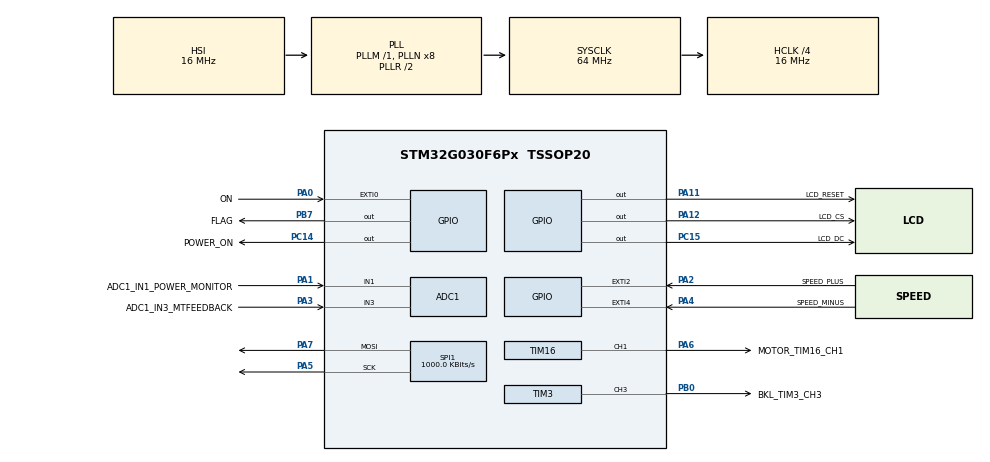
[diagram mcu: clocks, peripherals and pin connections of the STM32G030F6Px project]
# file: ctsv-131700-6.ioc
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ADC1.Channel-0\#ChannelRegularConversion=ADC_CHANNEL_1
ADC1.Channel-1\#ChannelRegularConversion=ADC_CHANNEL_3
ADC1.ContinuousConvMode=ENABLE
ADC1.DMAContinuousRequests=ENABLE
ADC1.EOCSelection=ADC_EOC_SEQ_CONV
ADC1.ExternalTrigConv=ADC_EXTERNALTRIG_T1_TRGO2
ADC1.NbrOfConversion=2
ADC1.NbrOfConversionFlag=1
ADC1.Rank-0\#ChannelRegularConversion=1
ADC1.Rank-1\#ChannelRegularConversion=2
ADC1.SamplingTime-0\#ChannelRegularConversion=ADC_SAMPLINGTIME_COMMON_1
ADC1.SamplingTime-1\#ChannelRegularConversion=ADC_SAMPLINGTIME_COMMON_1
ADC1.SamplingTimeCommon1=ADC_SAMPLETIME_39CYCLES_5
ADC1.SamplingTimeCommon2=ADC_SAMPLETIME_7CYCLES_5
ADC1.SelectedChannel=ADC_CHANNEL_1|ADC_CHANNEL_3
ADC1.TriggerFrequencyMode=ADC_TRIGGER_FREQ_LOW
ADC1.master=1
Dma.ADC1.0.Direction=DMA_PERIPH_TO_MEMORY
Dma.ADC1.0.EventEnable=DISABLE
Dma.ADC1.0.Instance=DMA1_Channel1
Dma.ADC1.0.MemDataAlignment=DMA_MDATAALIGN_HALFWORD
Dma.ADC1.0.MemInc=DMA_MINC_ENABLE
Dma.ADC1.0.Mode=DMA_CIRCULAR
Dma.ADC1.0.PeriphDataAlignment=DMA_PDATAALIGN_HALFWORD
Dma.ADC1.0.PeriphInc=DMA_PINC_DISABLE
Dma.ADC1.0.Polarity=HAL_DMAMUX_REQ_GEN_RISING
Dma.ADC1.0.Priority=DMA_PRIORITY_LOW
Dma.ADC1.0.RequestNumber=1
Dma.ADC1.0.SignalID=NONE
Dma.ADC1.0.SyncEnable=DISABLE
Dma.ADC1.0.SyncPolarity=HAL_DMAMUX_SYNC_NO_EVENT
Dma.ADC1.0.SyncRequestNumber=1
Dma.ADC1.0.SyncSignalID=NONE
Dma.Request0=ADC1
Mcu.Family=STM32G0
Mcu.Name=STM32G030F6Px
Mcu.Package=TSSOP20
NVIC.DMA1_Channel1_IRQn=true\:0\:0\:false\:false\:true\:false\:true
NVIC.EXTI0_1_IRQn=true\:0\:0\:false\:false\:true\:true\:true
NVIC.EXTI2_3_IRQn=true\:0\:0\:false\:false\:true\:true\:true
NVIC.EXTI4_15_IRQn=true\:0\:0\:false\:false\:true\:true\:true
NVIC.TIM16_IRQn=true\:0\:0\:false\:false\:true\:true\:true
NVIC.TIM17_IRQn=true\:0\:0\:false\:false\:true\:true\:true
PA0.GPIO_Label=ON
PA0.GPIO_ModeDefaultEXTI=GPIO_MODE_IT_FALLING
PA0.GPIO_PuPd=GPIO_PULLUP
PA0.Signal=GPXTI0
PA1.GPIO_Label=ADC1_IN1_POWER_MONITOR
PA1.Mode=IN1
PA1.Signal=ADC1_IN1
PA11\ [PA9].GPIO_Label=LCD_RESET
PA11\ [PA9].Signal=GPIO_Output
PA12\ [PA10].GPIO_Label=LCD_CS
PA12\ [PA10].Signal=GPIO_Output
PA13.Mode=Serial_Wire
PA13.Signal=SYS_SWDIO
PA14-BOOT0.Mode=Serial_Wire
PA14-BOOT0.Signal=SYS_SWCLK
PA2.GPIO_Label=SPEED_PLUS
PA2.GPIO_ModeDefaultEXTI=GPIO_MODE_IT_FALLING
PA2.GPIO_PuPd=GPIO_PULLUP
PA2.Signal=GPXTI2
PA3.GPIO_Label=ADC1_IN3_MTFEEDBACK
PA3.Mode=IN3
PA3.Signal=ADC1_IN3
PA4.GPIO_Label=SPEED_MINUS
PA4.GPIO_ModeDefaultEXTI=GPIO_MODE_IT_FALLING
PA4.GPIO_PuPd=GPIO_PULLUP
PA4.Signal=GPXTI4
PA5.Mode=TX_Only_Simplex_Unidirect_Master
PA5.Signal=SPI1_SCK
PA6.GPIO_Label=MOTOR_TIM16_CH1
PA6.Signal=S_TIM16_CH1
PA7.Mode=TX_Only_Simplex_Unidirect_Master
PA7.Signal=SPI1_MOSI
PB0.GPIO_Label=BKL_TIM3_CH3
PB0.Signal=S_TIM3_CH3
PB7.GPIO_Label=FLAG
PB7.Signal=GPIO_Output
PC14-OSC32_IN\ (PC14).GPIO_Label=POWER_ON
PC14-OSC32_IN\ (PC14).PinState=GPIO_PIN_SET
PC14-OSC32_IN\ (PC14).Signal=GPIO_Output
PC15-OSC32_OUT\ (PC15).GPIO_Label=LCD_DC
PC15-OSC32_OUT\ (PC15).Signal=GPIO_Output
ProjectManager.HeapSize=0x200
ProjectManager.StackSize=0x400
ProjectManager.TargetToolchain=STM32CubeIDE
RCC.ADCCLockSelection=RCC_ADCCLKSOURCE_PLLADC
RCC.ADCFreq_Value=4000000
RCC.AHBCLKDivider=RCC_SYSCLK_DIV4
RCC.AHBFreq_Value=16000000
RCC.APB1CLKDivider=RCC_HCLK_DIV8
RCC.CortexFreq_Value=16000000
RCC.DATA_CACHE_ENABLE=0
RCC.EXTERNAL_CLOCK_VALUE=12288000
RCC.HCLKFreq_Value=16000000
RCC.HSE_VALUE=8000000
RCC.HSI_VALUE=16000000
RCC.INSTRUCTION_CACHE_ENABLE=1
RCC.LSE_VALUE=32768
RCC.PLLP=RCC_PLLP_DIV32
RCC.SYSCLKFreq_VALUE=64000000
RCC.SYSCLKSource=RCC_SYSCLKSOURCE_PLLCLK
RCC.USART1CLockSelection=RCC_USART1CLKSOURCE_HSI
RCC.VCOOutputFreq_Value=128000000
RCC.VDD_VALUE=2
SH.S_TIM16_CH1.0=TIM16_CH1,PWM Generation1 CH1
SH.S_TIM3_CH3.0=TIM3_CH3,PWM Generation3 CH3
SPI1.BaudRatePrescaler=SPI_BAUDRATEPRESCALER_2
SPI1.CalculateBaudRate=1000.0 KBits/s
SPI1.Direction=SPI_DIRECTION_2LINES
SPI1.Mode=SPI_MODE_MASTER
SPI1.VirtualType=VM_MASTER
TIM1.Period=20000
TIM1.Prescaler=4
TIM1.TIM_MasterOutputTrigger=TIM_TRGO_UPDATE
TIM1.TIM_MasterOutputTrigger2=TIM_TRGO2_UPDATE
TIM16.Channel=TIM_CHANNEL_1
TIM16.Period=10000
TIM16.Prescaler=32
TIM16.Pulse=500
TIM17.Period=10000
TIM17.Prescaler=640
TIM3.Channel-PWM\ Generation3\ CH3=TIM_CHANNEL_3
TIM3.Period=10000
TIM3.Prescaler=4
TIM3.Pulse-PWM\ Generation3\ CH3=5000
VP_TIM16_VS_ClockSourceINT.Mode=Enable_Timer
VP_TIM17_VS_ClockSourceINT.Mode=Enable_Timer
VP_TIM1_VS_ClockSourceINT.Mode=Internal
board=custom

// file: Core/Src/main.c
/* USER CODE BEGIN Header */
/**
  ******************************************************************************
  * @file           : main.c
  * @brief          : Main program body
  ******************************************************************************
  * @attention
  *
  * <h2><center>&copy; Copyright (c) 2021 STMicroelectronics.
  * All rights reserved.</center></h2>
  *
  * This software component is licensed by ST under BSD 3-Clause license,
  * the "License"; You may not use this file except in compliance with the
  * License. You may obtain a copy of the License at:
  *                        opensource.org/licenses/BSD-3-Clause
  *
  ******************************************************************************
  */
/* USER CODE END Header */
#include "main.h"

ADC_HandleTypeDef hadc1;
DMA_HandleTypeDef hdma_adc1;

SPI_HandleTypeDef hspi1;

TIM_HandleTypeDef htim1;
TIM_HandleTypeDef htim3;
TIM_HandleTypeDef htim16;
TIM_HandleTypeDef htim17;

void SystemClock_Config(void);
static void MX_GPIO_Init(void);
static void MX_DMA_Init(void);
static void MX_ADC1_Init(void);
static void MX_SPI1_Init(void);
static void MX_TIM3_Init(void);
static void MX_TIM16_Init(void);
static void MX_TIM17_Init(void);
static void MX_TIM1_Init(void);

int main(void)
{

  /* MCU Configuration--------------------------------------------------------*/

  /* Reset of all peripherals, Initializes the Flash interface and the Systick. */
  HAL_Init();

  /* Configure the system clock */
  SystemClock_Config();

  /* Initialize all configured peripherals */
  MX_GPIO_Init();
  MX_DMA_Init();
  MX_ADC1_Init();
  MX_SPI1_Init();
  MX_TIM3_Init();
  MX_TIM16_Init();
  MX_TIM17_Init();
  MX_TIM1_Init();
  /* USER CODE BEGIN 2 */
  SurgyInit();
  /* USER CODE END 2 */

  /* Infinite loop */
  /* USER CODE BEGIN WHILE */
  while (1)
  {
	  SurgyMainLoop();
    /* USER CODE END WHILE */

  }
}

void SystemClock_Config(void)
{
  RCC_OscInitTypeDef RCC_OscInitStruct = {0};
  RCC_ClkInitTypeDef RCC_ClkInitStruct = {0};
  RCC_PeriphCLKInitTypeDef PeriphClkInit = {0};

  /** Configure the main internal regulator output voltage
  */
  HAL_PWREx_ControlVoltageScaling(PWR_REGULATOR_VOLTAGE_SCALE1);
  /** Initializes the RCC Oscillators according to the specified parameters
  * in the RCC_OscInitTypeDef structure.
  */
  RCC_OscInitStruct.OscillatorType = RCC_OSCILLATORTYPE_HSI;
  RCC_OscInitStruct.HSIState = RCC_HSI_ON;
  RCC_OscInitStruct.HSIDiv = RCC_HSI_DIV1;
  RCC_OscInitStruct.HSICalibrationValue = RCC_HSICALIBRATION_DEFAULT;
  RCC_OscInitStruct.PLL.PLLState = RCC_PLL_ON;
  RCC_OscInitStruct.PLL.PLLSource = RCC_PLLSOURCE_HSI;
  RCC_OscInitStruct.PLL.PLLM = RCC_PLLM_DIV1;
  RCC_OscInitStruct.PLL.PLLN = 8;
  RCC_OscInitStruct.PLL.PLLP = RCC_PLLP_DIV32;
  RCC_OscInitStruct.PLL.PLLR = RCC_PLLR_DIV2;
  if (HAL_RCC_OscConfig(&RCC_OscInitStruct) != HAL_OK)
  {
    Error_Handler();
  }
  /** Initializes the CPU, AHB and APB buses clocks
  */
  RCC_ClkInitStruct.ClockType = RCC_CLOCKTYPE_HCLK|RCC_CLOCKTYPE_SYSCLK
                              |RCC_CLOCKTYPE_PCLK1;
  RCC_ClkInitStruct.SYSCLKSource = RCC_SYSCLKSOURCE_PLLCLK;
  RCC_ClkInitStruct.AHBCLKDivider = RCC_SYSCLK_DIV4;
  RCC_ClkInitStruct.APB1CLKDivider = RCC_HCLK_DIV8;

  if (HAL_RCC_ClockConfig(&RCC_ClkInitStruct, FLASH_LATENCY_0) != HAL_OK)
  {
    Error_Handler();
  }
  /** Initializes the peripherals clocks
  */
  PeriphClkInit.PeriphClockSelection = RCC_PERIPHCLK_ADC;
  PeriphClkInit.AdcClockSelection = RCC_ADCCLKSOURCE_PLLADC;
  if (HAL_RCCEx_PeriphCLKConfig(&PeriphClkInit) != HAL_OK)
  {
    Error_Handler();
  }
}

static void MX_ADC1_Init(void)
{

  ADC_ChannelConfTypeDef sConfig = {0};

  /** Configure the global features of the ADC (Clock, Resolution, Data Alignment and number of conversion)
  */
  hadc1.Instance = ADC1;
  hadc1.Init.ClockPrescaler = ADC_CLOCK_SYNC_PCLK_DIV2;
  hadc1.Init.Resolution = ADC_RESOLUTION_12B;
  hadc1.Init.DataAlign = ADC_DATAALIGN_RIGHT;
  hadc1.Init.ScanConvMode = ADC_SCAN_ENABLE;
  hadc1.Init.EOCSelection = ADC_EOC_SEQ_CONV;
  hadc1.Init.LowPowerAutoWait = DISABLE;
  hadc1.Init.LowPowerAutoPowerOff = DISABLE;
  hadc1.Init.ContinuousConvMode = ENABLE;
  hadc1.Init.NbrOfConversion = 2;
  hadc1.Init.DiscontinuousConvMode = DISABLE;
  hadc1.Init.ExternalTrigConv = ADC_EXTERNALTRIG_T1_TRGO2;
  hadc1.Init.ExternalTrigConvEdge = ADC_EXTERNALTRIGCONVEDGE_RISING;
  hadc1.Init.DMAContinuousRequests = ENABLE;
  hadc1.Init.Overrun = ADC_OVR_DATA_PRESERVED;
  hadc1.Init.SamplingTimeCommon1 = ADC_SAMPLETIME_39CYCLES_5;
  hadc1.Init.SamplingTimeCommon2 = ADC_SAMPLETIME_7CYCLES_5;
  hadc1.Init.OversamplingMode = DISABLE;
  hadc1.Init.TriggerFrequencyMode = ADC_TRIGGER_FREQ_LOW;
  if (HAL_ADC_Init(&hadc1) != HAL_OK)
  {
    Error_Handler();
  }
  /** Configure Regular Channel
  */
  sConfig.Channel = ADC_CHANNEL_1;
  sConfig.Rank = ADC_REGULAR_RANK_1;
  sConfig.SamplingTime = ADC_SAMPLINGTIME_COMMON_1;
  if (HAL_ADC_ConfigChannel(&hadc1, &sConfig) != HAL_OK)
  {
    Error_Handler();
  }
  /** Configure Regular Channel
  */
  sConfig.Channel = ADC_CHANNEL_3;
  sConfig.Rank = ADC_REGULAR_RANK_2;
  if (HAL_ADC_ConfigChannel(&hadc1, &sConfig) != HAL_OK)
  {
    Error_Handler();
  }

}

static void MX_SPI1_Init(void)
{

  /* SPI1 parameter configuration*/
  hspi1.Instance = SPI1;
  hspi1.Init.Mode = SPI_MODE_MASTER;
  hspi1.Init.Direction = SPI_DIRECTION_2LINES;
  hspi1.Init.DataSize = SPI_DATASIZE_8BIT;
  hspi1.Init.CLKPolarity = SPI_POLARITY_LOW;
  hspi1.Init.CLKPhase = SPI_PHASE_1EDGE;
  hspi1.Init.NSS = SPI_NSS_SOFT;
  hspi1.Init.BaudRatePrescaler = SPI_BAUDRATEPRESCALER_2;
  hspi1.Init.FirstBit = SPI_FIRSTBIT_MSB;
  hspi1.Init.TIMode = SPI_TIMODE_DISABLE;
  hspi1.Init.CRCCalculation = SPI_CRCCALCULATION_DISABLE;
  hspi1.Init.CRCPolynomial = 7;
  hspi1.Init.CRCLength = SPI_CRC_LENGTH_DATASIZE;
  hspi1.Init.NSSPMode = SPI_NSS_PULSE_ENABLE;
  if (HAL_SPI_Init(&hspi1) != HAL_OK)
  {
    Error_Handler();
  }

}

static void MX_TIM1_Init(void)
{

  TIM_ClockConfigTypeDef sClockSourceConfig = {0};
  TIM_MasterConfigTypeDef sMasterConfig = {0};
  TIM_BreakDeadTimeConfigTypeDef sBreakDeadTimeConfig = {0};

  htim1.Instance = TIM1;
  htim1.Init.Prescaler = 4;
  htim1.Init.CounterMode = TIM_COUNTERMODE_UP;
  htim1.Init.Period = 20000;
  htim1.Init.ClockDivision = TIM_CLOCKDIVISION_DIV1;
  htim1.Init.RepetitionCounter = 0;
  htim1.Init.AutoReloadPreload = TIM_AUTORELOAD_PRELOAD_DISABLE;
  if (HAL_TIM_Base_Init(&htim1) != HAL_OK)
  {
    Error_Handler();
  }
  sClockSourceConfig.ClockSource = TIM_CLOCKSOURCE_INTERNAL;
  if (HAL_TIM_ConfigClockSource(&htim1, &sClockSourceConfig) != HAL_OK)
  {
    Error_Handler();
  }
  sMasterConfig.MasterOutputTrigger = TIM_TRGO_UPDATE;
  sMasterConfig.MasterOutputTrigger2 = TIM_TRGO2_UPDATE;
  sMasterConfig.MasterSlaveMode = TIM_MASTERSLAVEMODE_DISABLE;
  if (HAL_TIMEx_MasterConfigSynchronization(&htim1, &sMasterConfig) != HAL_OK)
  {
    Error_Handler();
  }
  sBreakDeadTimeConfig.BreakAFMode = TIM_BREAK_AFMODE_INPUT;
  sBreakDeadTimeConfig.Break2AFMode = TIM_BREAK_AFMODE_INPUT;
  if (HAL_TIMEx_ConfigBreakDeadTime(&htim1, &sBreakDeadTimeConfig) != HAL_OK)
  {
    Error_Handler();
  }

}

static void MX_TIM3_Init(void)
{

  TIM_MasterConfigTypeDef sMasterConfig = {0};
  TIM_OC_InitTypeDef sConfigOC = {0};

  htim3.Instance = TIM3;
  htim3.Init.Prescaler = 4;
  htim3.Init.CounterMode = TIM_COUNTERMODE_UP;
  htim3.Init.Period = 10000;
  htim3.Init.ClockDivision = TIM_CLOCKDIVISION_DIV1;
  htim3.Init.AutoReloadPreload = TIM_AUTORELOAD_PRELOAD_DISABLE;
  if (HAL_TIM_PWM_Init(&htim3) != HAL_OK)
  {
    Error_Handler();
  }
  sMasterConfig.MasterOutputTrigger = TIM_TRGO_RESET;
  sMasterConfig.MasterSlaveMode = TIM_MASTERSLAVEMODE_DISABLE;
  if (HAL_TIMEx_MasterConfigSynchronization(&htim3, &sMasterConfig) != HAL_OK)
  {
    Error_Handler();
  }
  sConfigOC.OCMode = TIM_OCMODE_PWM1;
  sConfigOC.Pulse = 5000;
  sConfigOC.OCPolarity = TIM_OCPOLARITY_HIGH;
  sConfigOC.OCFastMode = TIM_OCFAST_DISABLE;
  if (HAL_TIM_PWM_ConfigChannel(&htim3, &sConfigOC, TIM_CHANNEL_3) != HAL_OK)
  {
    Error_Handler();
  }
  HAL_TIM_MspPostInit(&htim3);

}

static void MX_TIM16_Init(void)
{

  TIM_OC_InitTypeDef sConfigOC = {0};
  TIM_BreakDeadTimeConfigTypeDef sBreakDeadTimeConfig = {0};

  htim16.Instance = TIM16;
  htim16.Init.Prescaler = 32;
  htim16.Init.CounterMode = TIM_COUNTERMODE_UP;
  htim16.Init.Period = 10000;
  htim16.Init.ClockDivision = TIM_CLOCKDIVISION_DIV1;
  htim16.Init.RepetitionCounter = 0;
  htim16.Init.AutoReloadPreload = TIM_AUTORELOAD_PRELOAD_DISABLE;
  if (HAL_TIM_Base_Init(&htim16) != HAL_OK)
  {
    Error_Handler();
  }
  if (HAL_TIM_PWM_Init(&htim16) != HAL_OK)
  {
    Error_Handler();
  }
  sConfigOC.OCMode = TIM_OCMODE_PWM1;
  sConfigOC.Pulse = 500;
  sConfigOC.OCPolarity = TIM_OCPOLARITY_HIGH;
  sConfigOC.OCNPolarity = TIM_OCNPOLARITY_HIGH;
  sConfigOC.OCFastMode = TIM_OCFAST_DISABLE;
  sConfigOC.OCIdleState = TIM_OCIDLESTATE_RESET;
  sConfigOC.OCNIdleState = TIM_OCNIDLESTATE_RESET;
  if (HAL_TIM_PWM_ConfigChannel(&htim16, &sConfigOC, TIM_CHANNEL_1) != HAL_OK)
  {
    Error_Handler();
  }
  sBreakDeadTimeConfig.OffStateRunMode = TIM_OSSR_DISABLE;
  sBreakDeadTimeConfig.OffStateIDLEMode = TIM_OSSI_DISABLE;
  sBreakDeadTimeConfig.LockLevel = TIM_LOCKLEVEL_OFF;
  sBreakDeadTimeConfig.DeadTime = 0;
  sBreakDeadTimeConfig.BreakState = TIM_BREAK_DISABLE;
  sBreakDeadTimeConfig.BreakPolarity = TIM_BREAKPOLARITY_HIGH;
  sBreakDeadTimeConfig.BreakFilter = 0;
  sBreakDeadTimeConfig.AutomaticOutput = TIM_AUTOMATICOUTPUT_DISABLE;
  if (HAL_TIMEx_ConfigBreakDeadTime(&htim16, &sBreakDeadTimeConfig) != HAL_OK)
  {
    Error_Handler();
  }
  HAL_TIM_MspPostInit(&htim16);

}

static void MX_TIM17_Init(void)
{

  htim17.Instance = TIM17;
  htim17.Init.Prescaler = 640;
  htim17.Init.CounterMode = TIM_COUNTERMODE_UP;
  htim17.Init.Period = 10000;
  htim17.Init.ClockDivision = TIM_CLOCKDIVISION_DIV1;
  htim17.Init.RepetitionCounter = 0;
  htim17.Init.AutoReloadPreload = TIM_AUTORELOAD_PRELOAD_DISABLE;
  if (HAL_TIM_Base_Init(&htim17) != HAL_OK)
  {
    Error_Handler();
  }

}

static void MX_DMA_Init(void)
{

  /* DMA controller clock enable */
  __HAL_RCC_DMA1_CLK_ENABLE();

  /* DMA interrupt init */
  /* DMA1_Channel1_IRQn interrupt configuration */
  HAL_NVIC_SetPriority(DMA1_Channel1_IRQn, 0, 0);
  HAL_NVIC_EnableIRQ(DMA1_Channel1_IRQn);

}

static void MX_GPIO_Init(void)
{
  GPIO_InitTypeDef GPIO_InitStruct = {0};

  /* GPIO Ports Clock Enable */
  __HAL_RCC_GPIOB_CLK_ENABLE();
  __HAL_RCC_GPIOC_CLK_ENABLE();
  __HAL_RCC_GPIOA_CLK_ENABLE();

  /*Configure GPIO pin Output Level */
  HAL_GPIO_WritePin(FLAG_GPIO_Port, FLAG_Pin, GPIO_PIN_RESET);

  /*Configure GPIO pin Output Level */
  HAL_GPIO_WritePin(POWER_ON_GPIO_Port, POWER_ON_Pin, GPIO_PIN_SET);

  /*Configure GPIO pin Output Level */
  HAL_GPIO_WritePin(LCD_DC_GPIO_Port, LCD_DC_Pin, GPIO_PIN_RESET);

  /*Configure GPIO pin Output Level */
  HAL_GPIO_WritePin(GPIOA, LCD_RESET_Pin|LCD_CS_Pin, GPIO_PIN_RESET);

  /*Configure GPIO pin : FLAG_Pin */
  GPIO_InitStruct.Pin = FLAG_Pin;
  GPIO_InitStruct.Mode = GPIO_MODE_OUTPUT_PP;
  GPIO_InitStruct.Pull = GPIO_NOPULL;
  GPIO_InitStruct.Speed = GPIO_SPEED_FREQ_LOW;
  HAL_GPIO_Init(FLAG_GPIO_Port, &GPIO_InitStruct);

  /*Configure GPIO pins : POWER_ON_Pin LCD_DC_Pin */
  GPIO_InitStruct.Pin = POWER_ON_Pin|LCD_DC_Pin;
  GPIO_InitStruct.Mode = GPIO_MODE_OUTPUT_PP;
  GPIO_InitStruct.Pull = GPIO_NOPULL;
  GPIO_InitStruct.Speed = GPIO_SPEED_FREQ_LOW;
  HAL_GPIO_Init(GPIOC, &GPIO_InitStruct);

  /*Configure GPIO pins : ON_Pin SPEED_PLUS_Pin SPEED_MINUS_Pin */
  GPIO_InitStruct.Pin = ON_Pin|SPEED_PLUS_Pin|SPEED_MINUS_Pin;
  GPIO_InitStruct.Mode = GPIO_MODE_IT_FALLING;
  GPIO_InitStruct.Pull = GPIO_PULLUP;
  HAL_GPIO_Init(GPIOA, &GPIO_InitStruct);

  /*Configure GPIO pins : LCD_RESET_Pin LCD_CS_Pin */
  GPIO_InitStruct.Pin = LCD_RESET_Pin|LCD_CS_Pin;
  GPIO_InitStruct.Mode = GPIO_MODE_OUTPUT_PP;
  GPIO_InitStruct.Pull = GPIO_NOPULL;
  GPIO_InitStruct.Speed = GPIO_SPEED_FREQ_LOW;
  HAL_GPIO_Init(GPIOA, &GPIO_InitStruct);

  /* EXTI interrupt init*/
  HAL_NVIC_SetPriority(EXTI0_1_IRQn, 0, 0);
  HAL_NVIC_EnableIRQ(EXTI0_1_IRQn);

  HAL_NVIC_SetPriority(EXTI2_3_IRQn, 0, 0);
  HAL_NVIC_EnableIRQ(EXTI2_3_IRQn);

  HAL_NVIC_SetPriority(EXTI4_15_IRQn, 0, 0);
  HAL_NVIC_EnableIRQ(EXTI4_15_IRQn);

}

void Error_Handler(void)
{
  __disable_irq();
  while (1)
  {
  }
}

/************************ (C) COPYRIGHT STMicroelectronics *****END OF FILE****/
